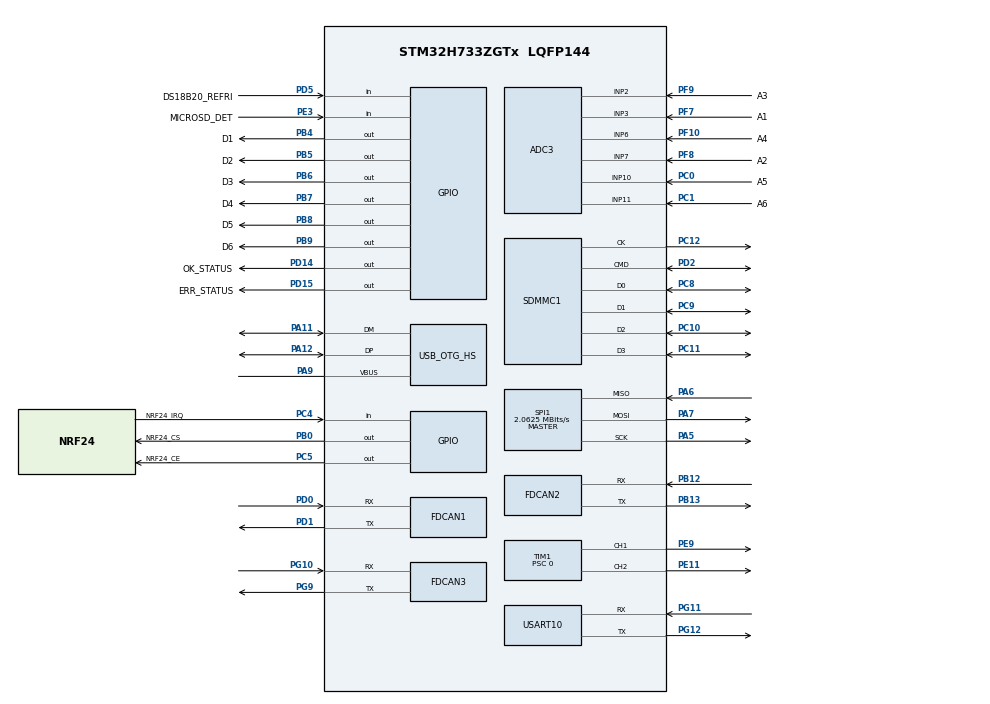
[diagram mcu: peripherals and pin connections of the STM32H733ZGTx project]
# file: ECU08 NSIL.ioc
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ADC3.Channel-0\#ChannelRegularConversion=ADC_CHANNEL_3
ADC3.NbrOfConversionFlag=1
ADC3.OffsetNumber-0\#ChannelRegularConversion=ADC_OFFSET_NONE
ADC3.OffsetSign-0\#ChannelRegularConversion=ADC3_OFFSET_SIGN_NEGATIVE
ADC3.Rank-0\#ChannelRegularConversion=1
ADC3.SamplingTime-0\#ChannelRegularConversion=ADC3_SAMPLETIME_2CYCLES_5
FDCAN1.AutoRetransmission=ENABLE
FDCAN1.CalculateBaudRateNominal=500000
FDCAN1.CalculateTimeBitNominal=2000
FDCAN1.CalculateTimeQuantumNominal=250.0
FDCAN1.ExtFiltersNbr=1
FDCAN1.NominalPrescaler=6
FDCAN1.NominalTimeSeg1=2
FDCAN1.NominalTimeSeg2=5
FDCAN1.RxBuffersNbr=0
FDCAN1.RxFifo0ElmtsNbr=32
FDCAN1.RxFifo1ElmtsNbr=32
FDCAN1.StdFiltersNbr=1
FDCAN1.TxBuffersNbr=0
FDCAN1.TxEventsNbr=0
FDCAN1.TxFifoQueueElmtsNbr=32
FDCAN2.CalculateBaudRateNominal=500000
FDCAN2.CalculateTimeBitNominal=2000
FDCAN2.CalculateTimeQuantumNominal=250.0
FDCAN2.ExtFiltersNbr=1
FDCAN2.FrameFormat=FDCAN_FRAME_CLASSIC
FDCAN2.NominalPrescaler=6
FDCAN2.NominalTimeSeg1=2
FDCAN2.NominalTimeSeg2=5
FDCAN2.RxBuffersNbr=0
FDCAN2.RxFifo0ElmtSize=FDCAN_DATA_BYTES_8
FDCAN2.RxFifo0ElmtsNbr=16
FDCAN2.RxFifo1ElmtsNbr=16
FDCAN2.StdFiltersNbr=1
FDCAN2.TxBuffersNbr=0
FDCAN2.TxEventsNbr=0
FDCAN2.TxFifoQueueElmtsNbr=16
FDCAN3.CalculateBaudRateNominal=500000
FDCAN3.CalculateTimeBitNominal=2000
FDCAN3.CalculateTimeQuantumNominal=250.0
FDCAN3.ExtFiltersNbr=1
FDCAN3.NominalPrescaler=6
FDCAN3.NominalTimeSeg1=2
FDCAN3.NominalTimeSeg2=5
FDCAN3.RxFifo0ElmtsNbr=16
FDCAN3.RxFifo1ElmtsNbr=16
FDCAN3.StdFiltersNbr=1
FDCAN3.TxFifoQueueElmtsNbr=16
FREERTOS.Queues01=canRxQueue,32,uint32_t,0,Dynamic,NULL,NULL;canTxQueue,32,uint32_t,0,Dynamic,NULL,NULL
FREERTOS.Tasks01=defaultTask,24,128,StartDefaultTask,Default,NULL,Dynamic,NULL,NULL;App_InitTask,40,1024,StartAppInitTask,Default,NULL,Dynamic,NULL,NULL;ControlTask,40,1024,StartControlTask,Default,NULL,Dynamic,NULL,NULL;CanRxTask,40,1024,StartCanRxTask,Default,NULL,Dynamic,NULL,NULL;CanTxTask,32,1024,StartCanTxTask,Default,NULL,Dynamic,NULL,NULL;TelemetryTask,24,1024,StartTelemetryTask,Default,NULL,Dynamic,NULL,NULL;DiagTask,8,768,StartDiagTask,Default,NULL,Dynamic,NULL,NULL
FREERTOS.configUSE_NEWLIB_REENTRANT=1
Mcu.Family=STM32H7
Mcu.Name=STM32H733ZGTx
Mcu.Package=LQFP144
NVIC.FDCAN1_IT0_IRQn=true\:5\:0\:true\:false\:true\:true\:true\:true\:true
NVIC.FDCAN2_IT0_IRQn=true\:5\:0\:true\:false\:true\:true\:true\:true\:true
NVIC.FDCAN3_IT0_IRQn=true\:5\:0\:false\:false\:true\:true\:true\:true\:true
NVIC.PriorityGroup=NVIC_PRIORITYGROUP_4
NVIC.SDMMC1_IRQn=true\:5\:0\:false\:false\:true\:true\:true\:true\:true
NVIC.SPI1_IRQn=true\:5\:0\:false\:false\:true\:true\:true\:true\:true
NVIC.TIM16_IRQn=true\:5\:0\:false\:false\:true\:true\:true\:true\:true
NVIC.USART10_IRQn=true\:5\:0\:false\:false\:true\:true\:true\:true\:true
PA11.Mode=Device_Only_FS
PA11.Signal=USB_OTG_HS_DM
PA12.Mode=Device_Only_FS
PA12.Signal=USB_OTG_HS_DP
PA13(JTMS/SWDIO).Mode=Serial_Wire
PA13(JTMS/SWDIO).Signal=DEBUG_JTMS-SWDIO
PA14(JTCK/SWCLK).Mode=Serial_Wire
PA14(JTCK/SWCLK).Signal=DEBUG_JTCK-SWCLK
PA5.Mode=Full_Duplex_Master
PA5.Signal=SPI1_SCK
PA6.Mode=Full_Duplex_Master
PA6.Signal=SPI1_MISO
PA7.Mode=Full_Duplex_Master
PA7.Signal=SPI1_MOSI
PA9.Mode=Activate_VBUS_FS
PA9.Signal=USB_OTG_HS_VBUS
PB0.GPIO_Label=NRF24_CS
PB0.Signal=GPIO_Output
PB12.Mode=FDCAN_Activate
PB12.Signal=FDCAN2_RX
PB13.Mode=FDCAN_Activate
PB13.Signal=FDCAN2_TX
PB4(NJTRST).GPIO_Label=D1
PB4(NJTRST).Signal=GPIO_Output
PB5.GPIO_Label=D2
PB5.Signal=GPIO_Output
PB6.GPIO_Label=D3
PB6.Signal=GPIO_Output
PB7.GPIO_Label=D4
PB7.Signal=GPIO_Output
PB8.GPIO_Label=D5
PB8.Signal=GPIO_Output
PB9.GPIO_Label=D6
PB9.Signal=GPIO_Output
PC0.GPIO_Label=A5
PC0.Signal=ADCx_INP10
PC1.GPIO_Label=A6
PC1.Signal=ADCx_INP11
PC10.Mode=SD_4_bits_Wide_bus
PC10.Signal=SDMMC1_D2
PC11.Mode=SD_4_bits_Wide_bus
PC11.Signal=SDMMC1_D3
PC12.Mode=SD_4_bits_Wide_bus
PC12.Signal=SDMMC1_CK
PC4.GPIO_Label=NRF24_IRQ
PC4.Signal=GPIO_Input
PC5.GPIO_Label=NRF24_CE
PC5.Signal=GPIO_Output
PC8.Mode=SD_4_bits_Wide_bus
PC8.Signal=SDMMC1_D0
PC9.Mode=SD_4_bits_Wide_bus
PC9.Signal=SDMMC1_D1
PD0.Mode=FDCAN_Activate
PD0.Signal=FDCAN1_RX
PD1.Mode=FDCAN_Activate
PD1.Signal=FDCAN1_TX
PD14.GPIO_Label=OK_STATUS
PD14.Signal=GPIO_Output
PD15.GPIO_Label=ERR_STATUS
PD15.Signal=GPIO_Output
PD2.Mode=SD_4_bits_Wide_bus
PD2.Signal=SDMMC1_CMD
PD5.GPIO_Label=DS18B20_REFRI
PD5.Signal=GPIO_Input
PE11.Signal=S_TIM1_CH2
PE3.GPIO_Label=MICROSD_DET
PE3.Signal=GPIO_Input
PE9.Signal=S_TIM1_CH1
PF10.GPIO_Label=A4
PF10.Mode=IN6-Single-Ended
PF10.Signal=ADC3_INP6
PF7.GPIO_Label=A1
PF7.Mode=IN3-Single-Ended
PF7.Signal=ADC3_INP3
PF8.GPIO_Label=A2
PF8.Signal=SharedAnalog_PF8
PF9.GPIO_Label=A3
PF9.Mode=IN2-Single-Ended
PF9.Signal=ADC3_INP2
PG10.Mode=FDCAN_Activate
PG10.Signal=FDCAN3_RX
PG11.Mode=Asynchronous
PG11.Signal=USART10_RX
PG12.Mode=Asynchronous
PG12.Signal=USART10_TX
PG9.Mode=FDCAN_Activate
PG9.Signal=FDCAN3_TX
PH0-OSC_IN.Mode=HSE-External-Oscillator
PH0-OSC_IN.Signal=RCC_OSC_IN
PH1-OSC_OUT.Mode=HSE-External-Oscillator
PH1-OSC_OUT.Signal=RCC_OSC_OUT
ProjectManager.HeapSize=0x200
ProjectManager.StackSize=0x400
ProjectManager.TargetToolchain=STM32CubeIDE
RCC.ADCCLockSelection=RCC_ADCCLKSOURCE_PLL2
RCC.ADCFreq_Value=96000000
RCC.APB1Freq_Value=132000000
RCC.APB2Freq_Value=132000000
RCC.APB3Freq_Value=132000000
RCC.APB4Freq_Value=132000000
RCC.CECCLockSelection=RCC_CECCLKSOURCE_LSI
RCC.CKPERSourceSelection=RCC_CLKPSOURCE_HSI
RCC.CSI_VALUE=4000000
RCC.CortexFreq_Value=528000000
RCC.Cortex_DivARG=SystemCoreClock/1000
RCC.D1PPRE=RCC_APB3_DIV2
RCC.D2PPRE1=RCC_APB1_DIV2
RCC.D2PPRE2=RCC_APB2_DIV2
RCC.D3PPRE=RCC_APB4_DIV2
RCC.DFSDMCLockSelection=RCC_DFSDM1CLKSOURCE_D2PCLK1
RCC.DIVM1=2
RCC.DIVM2=2
RCC.DIVN1=44
RCC.DIVN2=16
RCC.DIVP1=1
RCC.DIVQ1=4
RCC.DIVR2=1
RCC.EXTERNAL_CLOCK_VALUE=12288000
RCC.FDCANCLockSelection=RCC_FDCANCLKSOURCE_HSE
RCC.FMCCLockSelection=RCC_FMCCLKSOURCE_D1HCLK
RCC.HCLKFreq_Value=264000000
RCC.HPRE=RCC_HCLK_DIV2
RCC.HSE_VALUE=24000000
RCC.HSI48_VALUE=48000000
RCC.HSI_VALUE=64000000
RCC.I2C123CLockSelection=RCC_I2C1235CLKSOURCE_D2PCLK1
RCC.I2C4CLockSelection=RCC_I2C4CLKSOURCE_D3PCLK1
RCC.LPTIM1CLockSelection=RCC_LPTIM1CLKSOURCE_D2PCLK1
RCC.LPTIM2CLockSelection=RCC_LPTIM2CLKSOURCE_D3PCLK1
RCC.LPTIM345CLockSelection=RCC_LPTIM345CLKSOURCE_D3PCLK1
RCC.LPUART1CLockSelection=RCC_LPUART1CLKSOURCE_D3PCLK1
RCC.LSE_VALUE=32768
RCC.PLL2FRACN=0
RCC.PLL3FRACN=0
RCC.PLLFRACN=0
RCC.PLLSourceVirtual=RCC_PLLSOURCE_HSE
RCC.QSPICLockSelection=RCC_OSPICLKSOURCE_D1HCLK
RCC.RCC_MCO1Source=RCC_MCO1SOURCE_HSI
RCC.RCC_MCO2Source=RCC_MCO2SOURCE_SYSCLK
RCC.RNGCLockSelection=RCC_RNGCLKSOURCE_HSI48
RCC.SAI1CLockSelection=RCC_SAI1CLKSOURCE_PLL
RCC.SAI4ACLockSelection=RCC_SAI4ACLKSOURCE_PLL
RCC.SAI4BCLockSelection=RCC_SAI4BCLKSOURCE_PLL
RCC.SDMMC1CLockSelection=RCC_SDMMCCLKSOURCE_PLL2
RCC.SPDIFCLockSelection=RCC_SPDIFRXCLKSOURCE_PLL
RCC.SPI123CLockSelection=RCC_SPI123CLKSOURCE_PLL
RCC.SPI6CLockSelection=RCC_SPI6CLKSOURCE_D3PCLK1
RCC.SWPCLockSelection=RCC_SWPMI1CLKSOURCE_D2PCLK1
RCC.SYSCLKFreq_VALUE=528000000
RCC.SYSCLKSource=RCC_SYSCLKSOURCE_PLLCLK
RCC.Spi45ClockSelection=RCC_SPI45CLKSOURCE_D2PCLK1
RCC.USART16CLockSelection=RCC_USART16910CLKSOURCE_D2PCLK2
RCC.USART234578CLockSelection=RCC_USART234578CLKSOURCE_D2PCLK1
RCC.USBCLockSelection=RCC_USBCLKSOURCE_HSI48
RCC.USBFreq_Value=48000000
SDMMC1.ClockDiv=2
SH.ADCx_INP10.0=ADC3_INP10,IN10-Single-Ended
SH.ADCx_INP11.0=ADC3_INP11,IN11-Single-Ended
SH.S_TIM1_CH1.0=TIM1_CH1,PWM Generation1 CH1
SH.S_TIM1_CH2.0=TIM1_CH2,PWM Generation2 CH2
SH.SharedAnalog_PF8.0=ADC3_INN3
SH.SharedAnalog_PF8.1=ADC3_INP7,IN7-Single-Ended
SPI1.BaudRatePrescaler=SPI_BAUDRATEPRESCALER_64
SPI1.CalculateBaudRate=2.0625 MBits/s
SPI1.DataSize=SPI_DATASIZE_8BIT
SPI1.Direction=SPI_DIRECTION_2LINES
SPI1.Mode=SPI_MODE_MASTER
SPI1.NSSPMode=SPI_NSS_PULSE_DISABLE
SPI1.VirtualType=VM_MASTER
TIM1.AutoReloadPreload=TIM_AUTORELOAD_PRELOAD_ENABLE
TIM1.Channel-PWM\ Generation1\ CH1=TIM_CHANNEL_1
TIM1.Channel-PWM\ Generation2\ CH2=TIM_CHANNEL_2
TIM1.Period=65535
TIM1.Prescaler=0
TIM16.Period=10000 - 1
TIM16.Prescaler=528
USART10.VirtualMode-Asynchronous=VM_ASYNC
USB_OTG_HS.VirtualMode-Device_Only_FS=Device_Only_FS
VP_FREERTOS_VS_CMSIS_V2.Mode=CMSIS_V2
VP_MEMORYMAP_VS_MEMORYMAP.Mode=CurAppReg
VP_TIM16_VS_ClockSourceINT.Mode=Enable_Timer
VP_TIM1_VS_ClockSourceINT.Mode=Internal
board=custom

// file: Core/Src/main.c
/* USER CODE BEGIN Header */
/**
  ******************************************************************************
  * @file           : main.c
  * @brief          : Main program body
  ******************************************************************************
  * @attention
  *
  * Copyright (c) 2026 STMicroelectronics.
  * All rights reserved.
  *
  * This software is licensed under terms that can be found in the LICENSE file
  * in the root directory of this software component.
  * If no LICENSE file comes with this software, it is provided AS-IS.
  *
  ******************************************************************************
  */
/* USER CODE END Header */
#include "main.h"
#include "cmsis_os.h"
#include "adc.h"
#include "fdcan.h"
#include "memorymap.h"
#include "sdmmc.h"
#include "spi.h"
#include "tim.h"
#include "usart.h"
#include "usb_otg.h"
#include "gpio.h"

void SystemClock_Config(void);
void PeriphCommonClock_Config(void);
void MX_FREERTOS_Init(void);

int main(void)
{

  /* MCU Configuration--------------------------------------------------------*/

  /* Reset of all peripherals, Initializes the Flash interface and the Systick. */
  HAL_Init();

  /* Configure the system clock */
  SystemClock_Config();

  /* Configure the peripherals common clocks */
  PeriphCommonClock_Config();

  /* Initialize all configured peripherals */
  MX_GPIO_Init();
  MX_FDCAN1_Init();
  MX_FDCAN2_Init();
  MX_TIM1_Init();
  MX_TIM16_Init();
  MX_FDCAN3_Init();
  MX_ADC3_Init();
  MX_USART10_UART_Init();
  MX_SDMMC1_SD_Init();
  MX_SPI1_Init();
  MX_USB_OTG_HS_PCD_Init();

  /* Init scheduler */
  osKernelInitialize();

  /* Call init function for freertos objects (in cmsis_os2.c) */
  MX_FREERTOS_Init();

  /* Start scheduler */
  osKernelStart();

  /* We should never get here as control is now taken by the scheduler */

  /* Infinite loop */
  while (1)
  {

  }
}

void SystemClock_Config(void)
{
  RCC_OscInitTypeDef RCC_OscInitStruct = {0};
  RCC_ClkInitTypeDef RCC_ClkInitStruct = {0};

  /** Supply configuration update enable
  */
  HAL_PWREx_ConfigSupply(PWR_LDO_SUPPLY);

  /** Configure the main internal regulator output voltage
  */
  __HAL_PWR_VOLTAGESCALING_CONFIG(PWR_REGULATOR_VOLTAGE_SCALE0);

  while(!__HAL_PWR_GET_FLAG(PWR_FLAG_VOSRDY)) {}

  /** Initializes the RCC Oscillators according to the specified parameters
  * in the RCC_OscInitTypeDef structure.
  */
  RCC_OscInitStruct.OscillatorType = RCC_OSCILLATORTYPE_HSI48|RCC_OSCILLATORTYPE_HSE;
  RCC_OscInitStruct.HSEState = RCC_HSE_ON;
  RCC_OscInitStruct.HSI48State = RCC_HSI48_ON;
  RCC_OscInitStruct.PLL.PLLState = RCC_PLL_ON;
  RCC_OscInitStruct.PLL.PLLSource = RCC_PLLSOURCE_HSE;
  RCC_OscInitStruct.PLL.PLLM = 2;
  RCC_OscInitStruct.PLL.PLLN = 44;
  RCC_OscInitStruct.PLL.PLLP = 1;
  RCC_OscInitStruct.PLL.PLLQ = 4;
  RCC_OscInitStruct.PLL.PLLR = 2;
  RCC_OscInitStruct.PLL.PLLRGE = RCC_PLL1VCIRANGE_3;
  RCC_OscInitStruct.PLL.PLLVCOSEL = RCC_PLL1VCOWIDE;
  RCC_OscInitStruct.PLL.PLLFRACN = 0;
  if (HAL_RCC_OscConfig(&RCC_OscInitStruct) != HAL_OK)
  {
    Error_Handler();
  }

  /** Initializes the CPU, AHB and APB buses clocks
  */
  RCC_ClkInitStruct.ClockType = RCC_CLOCKTYPE_HCLK|RCC_CLOCKTYPE_SYSCLK
                              |RCC_CLOCKTYPE_PCLK1|RCC_CLOCKTYPE_PCLK2
                              |RCC_CLOCKTYPE_D3PCLK1|RCC_CLOCKTYPE_D1PCLK1;
  RCC_ClkInitStruct.SYSCLKSource = RCC_SYSCLKSOURCE_PLLCLK;
  RCC_ClkInitStruct.SYSCLKDivider = RCC_SYSCLK_DIV1;
  RCC_ClkInitStruct.AHBCLKDivider = RCC_HCLK_DIV2;
  RCC_ClkInitStruct.APB3CLKDivider = RCC_APB3_DIV2;
  RCC_ClkInitStruct.APB1CLKDivider = RCC_APB1_DIV2;
  RCC_ClkInitStruct.APB2CLKDivider = RCC_APB2_DIV2;
  RCC_ClkInitStruct.APB4CLKDivider = RCC_APB4_DIV2;

  if (HAL_RCC_ClockConfig(&RCC_ClkInitStruct, FLASH_LATENCY_3) != HAL_OK)
  {
    Error_Handler();
  }
}

void PeriphCommonClock_Config(void)
{
  RCC_PeriphCLKInitTypeDef PeriphClkInitStruct = {0};

  /** Initializes the peripherals clock
  */
  PeriphClkInitStruct.PeriphClockSelection = RCC_PERIPHCLK_ADC|RCC_PERIPHCLK_SDMMC;
  PeriphClkInitStruct.PLL2.PLL2M = 2;
  PeriphClkInitStruct.PLL2.PLL2N = 16;
  PeriphClkInitStruct.PLL2.PLL2P = 2;
  PeriphClkInitStruct.PLL2.PLL2Q = 2;
  PeriphClkInitStruct.PLL2.PLL2R = 1;
  PeriphClkInitStruct.PLL2.PLL2RGE = RCC_PLL2VCIRANGE_3;
  PeriphClkInitStruct.PLL2.PLL2VCOSEL = RCC_PLL2VCOWIDE;
  PeriphClkInitStruct.PLL2.PLL2FRACN = 0;
  PeriphClkInitStruct.SdmmcClockSelection = RCC_SDMMCCLKSOURCE_PLL2;
  PeriphClkInitStruct.AdcClockSelection = RCC_ADCCLKSOURCE_PLL2;
  if (HAL_RCCEx_PeriphCLKConfig(&PeriphClkInitStruct) != HAL_OK)
  {
    Error_Handler();
  }
}

void Error_Handler(void)
{
  __disable_irq();
  while (1)
  {
  }
}

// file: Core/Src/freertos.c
/* USER CODE BEGIN Header */
/**
  ******************************************************************************
  * File Name          : freertos.c
  * Description        : Code for freertos applications
  ******************************************************************************
  * @attention
  *
  * Copyright (c) 2026 STMicroelectronics.
  * All rights reserved.
  *
  * This software is licensed under terms that can be found in the LICENSE file
  * in the root directory of this software component.
  * If no LICENSE file comes with this software, it is provided AS-IS.
  *
  ******************************************************************************
  */
/* USER CODE END Header */

#include "FreeRTOS.h"
#include "task.h"
#include "main.h"
#include "cmsis_os.h"

/* Definitions for defaultTask */
osThreadId_t defaultTaskHandle;
const osThreadAttr_t defaultTask_attributes = {
  .name = "defaultTask",
  .stack_size = 128 * 4,
  .priority = (osPriority_t) osPriorityNormal,
};
/* Definitions for App_InitTask */
osThreadId_t App_InitTaskHandle;
const osThreadAttr_t App_InitTask_attributes = {
  .name = "App_InitTask",
  .stack_size = 1024 * 4,
  .priority = (osPriority_t) osPriorityHigh,
};
/* Definitions for ControlTask */
osThreadId_t ControlTaskHandle;
const osThreadAttr_t ControlTask_attributes = {
  .name = "ControlTask",
  .stack_size = 1024 * 4,
  .priority = (osPriority_t) osPriorityHigh,
};
/* Definitions for CanRxTask */
osThreadId_t CanRxTaskHandle;
const osThreadAttr_t CanRxTask_attributes = {
  .name = "CanRxTask",
  .stack_size = 1024 * 4,
  .priority = (osPriority_t) osPriorityHigh,
};
/* Definitions for CanTxTask */
osThreadId_t CanTxTaskHandle;
const osThreadAttr_t CanTxTask_attributes = {
  .name = "CanTxTask",
  .stack_size = 1024 * 4,
  .priority = (osPriority_t) osPriorityAboveNormal,
};
/* Definitions for TelemetryTask */
osThreadId_t TelemetryTaskHandle;
const osThreadAttr_t TelemetryTask_attributes = {
  .name = "TelemetryTask",
  .stack_size = 1024 * 4,
  .priority = (osPriority_t) osPriorityNormal,
};
/* Definitions for DiagTask */
osThreadId_t DiagTaskHandle;
const osThreadAttr_t DiagTask_attributes = {
  .name = "DiagTask",
  .stack_size = 768 * 4,
  .priority = (osPriority_t) osPriorityLow,
};
/* Definitions for canRxQueue */
osMessageQueueId_t canRxQueueHandle;
const osMessageQueueAttr_t canRxQueue_attributes = {
  .name = "canRxQueue"
};
/* Definitions for canTxQueue */
osMessageQueueId_t canTxQueueHandle;
const osMessageQueueAttr_t canTxQueue_attributes = {
  .name = "canTxQueue"
};

void StartDefaultTask(void *argument);
void StartAppInitTask(void *argument);
void StartControlTask(void *argument);
void StartCanRxTask(void *argument);
void StartCanTxTask(void *argument);
void StartTelemetryTask(void *argument);
void StartDiagTask(void *argument);

void MX_FREERTOS_Init(void); /* (MISRA C 2004 rule 8.1) */

void MX_FREERTOS_Init(void) {

  /* Create the queue(s) */
  /* creation of canRxQueue */
  canRxQueueHandle = osMessageQueueNew (32, sizeof(uint32_t), &canRxQueue_attributes);

  /* creation of canTxQueue */
  canTxQueueHandle = osMessageQueueNew (32, sizeof(uint32_t), &canTxQueue_attributes);

  /* Create the thread(s) */
  /* creation of defaultTask */
  defaultTaskHandle = osThreadNew(StartDefaultTask, NULL, &defaultTask_attributes);

  /* creation of App_InitTask */
  App_InitTaskHandle = osThreadNew(StartAppInitTask, NULL, &App_InitTask_attributes);

  /* creation of ControlTask */
  ControlTaskHandle = osThreadNew(StartControlTask, NULL, &ControlTask_attributes);

  /* creation of CanRxTask */
  CanRxTaskHandle = osThreadNew(StartCanRxTask, NULL, &CanRxTask_attributes);

  /* creation of CanTxTask */
  CanTxTaskHandle = osThreadNew(StartCanTxTask, NULL, &CanTxTask_attributes);

  /* creation of TelemetryTask */
  TelemetryTaskHandle = osThreadNew(StartTelemetryTask, NULL, &TelemetryTask_attributes);

  /* creation of DiagTask */
  DiagTaskHandle = osThreadNew(StartDiagTask, NULL, &DiagTask_attributes);

}

void StartDefaultTask(void *argument)
{
  for(;;)
  {
    osDelay(1);
  }
}

void StartAppInitTask(void *argument)
{
  /* USER CODE BEGIN StartAppInitTask */
  /* Infinite loop */
	Secuencia_arranque();
	App_Init();
	//es equivalente a lo de abajo osThreadExit();
	/*
  for(;;)
  {
    osDelay(1000);
  }
  */
	osThreadExit();

  /* USER CODE END StartAppInitTask */
}

void StartControlTask(void *argument)
{
  /* USER CODE BEGIN StartControlTask */
  /* Infinite loop */
	ControlTask();
  for(;;)
  {
    osDelay(1);
  }
  /* USER CODE END StartControlTask */
}

void StartCanRxTask(void *argument)
{
  /* USER CODE BEGIN StartCanRxTask */
  /* Infinite loop */
	CanRxTask();
  for(;;)
  {
    osDelay(1);
  }
  /* USER CODE END StartCanRxTask */
}

void StartCanTxTask(void *argument)
{
  /* USER CODE BEGIN StartCanTxTask */
  /* Infinite loop */
	CanTxTask();
  for(;;)
  {
    osDelay(1);
  }
  /* USER CODE END StartCanTxTask */
}

void StartTelemetryTask(void *argument)
{
  /* USER CODE BEGIN StartTelemetryTask */
  /* Infinite loop */
	 TelemetryTask();
  for(;;)
  {
    osDelay(1);
  }
  /* USER CODE END StartTelemetryTask */
}

void StartDiagTask(void *argument)
{
  /* USER CODE BEGIN StartDiagTask */
  /* Infinite loop */
	DiagTask();
  for(;;)
  {
    osDelay(1);
  }
  /* USER CODE END StartDiagTask */
}
